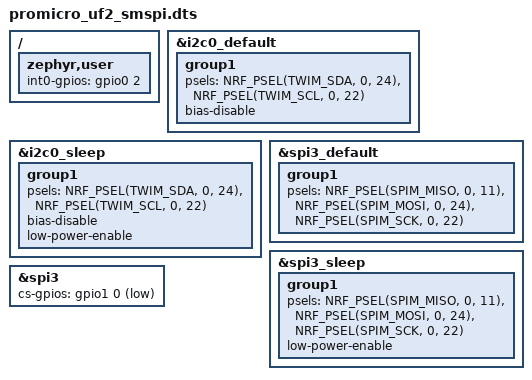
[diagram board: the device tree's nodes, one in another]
// Copyright (c) 2024 Nordic Semiconductor ASA
// SPDX-License-Identifier: Apache-2.0

/dts-v1/;
#include "promicro_uf2.dts"

&i2c0_default {
	group1 {
		psels = <NRF_PSEL(TWIM_SDA, 0, 24)>, <NRF_PSEL(TWIM_SCL, 0, 22)>;
		bias-disable;
	};
};

&i2c0_sleep {
	group1 {
		psels = <NRF_PSEL(TWIM_SDA, 0, 24)>, <NRF_PSEL(TWIM_SCL, 0, 22)>;
		bias-disable;
		low-power-enable;
	};
};

&spi3_default {
	group1 {
		psels = <NRF_PSEL(SPIM_MISO, 0, 11)>,
				<NRF_PSEL(SPIM_MOSI, 0, 24)>,
				<NRF_PSEL(SPIM_SCK, 0, 22)>;
	};
};

&spi3_sleep {
	group1 {
		psels = <NRF_PSEL(SPIM_MISO, 0, 11)>,
				<NRF_PSEL(SPIM_MOSI, 0, 24)>,
				<NRF_PSEL(SPIM_SCK, 0, 22)>;
		low-power-enable;
	};
};

/ {
	zephyr,user {
		int0-gpios = <&gpio0 2 0>;
		/delete-property/ clk-gpios;
	};
};

&spi3 {
	cs-gpios = <&gpio1 0 GPIO_ACTIVE_LOW>;
};
